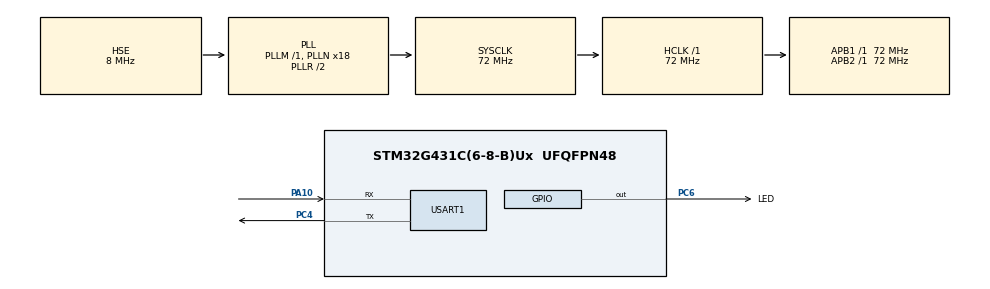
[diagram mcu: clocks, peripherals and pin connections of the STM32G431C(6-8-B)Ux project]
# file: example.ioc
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Mcu.Family=STM32G4
Mcu.Name=STM32G431C(6-8-B)Ux
Mcu.Package=UFQFPN48
NVIC.PriorityGroup=NVIC_PRIORITYGROUP_4
NVIC.TIM7_IRQn=true\:0\:0\:false\:false\:true\:true\:true\:true
PA10.Mode=Asynchronous
PA10.Signal=USART1_RX
PA13.Mode=Serial_Wire
PA13.Signal=SYS_JTMS-SWDIO
PA14.Mode=Serial_Wire
PA14.Signal=SYS_JTCK-SWCLK
PC4.Mode=Asynchronous
PC4.Signal=USART1_TX
PC6.GPIO_Label=LED
PC6.Signal=GPIO_Output
PF0-OSC_IN.Mode=HSE-External-Oscillator
PF0-OSC_IN.Signal=RCC_OSC_IN
PF1-OSC_OUT.Mode=HSE-External-Oscillator
PF1-OSC_OUT.Signal=RCC_OSC_OUT
ProjectManager.HeapSize=0x200
ProjectManager.StackSize=0x400
ProjectManager.TargetToolchain=CMake
RCC.ADC12Freq_Value=72000000
RCC.AHBFreq_Value=72000000
RCC.APB1Freq_Value=72000000
RCC.APB1TimFreq_Value=72000000
RCC.APB2Freq_Value=72000000
RCC.APB2TimFreq_Value=72000000
RCC.CortexFreq_Value=72000000
RCC.EXTERNAL_CLOCK_VALUE=12288000
RCC.HCLKFreq_Value=72000000
RCC.HSE_VALUE=8000000
RCC.HSI48_VALUE=48000000
RCC.HSI_VALUE=16000000
RCC.LSE_VALUE=32768
RCC.PLLN=18
RCC.PLLSourceVirtual=RCC_PLLSOURCE_HSE
RCC.SYSCLKFreq_VALUE=72000000
RCC.SYSCLKSource=RCC_SYSCLKSOURCE_PLLCLK
RCC.USBFreq_Value=72000000
RCC.VCOOutputFreq_Value=144000000
TIM7.PeriodNoDither=100-1
TIM7.Prescaler=72-1
USART1.VirtualMode-Asynchronous=VM_ASYNC
VP_SYS_VS_DBSignals.Mode=DisableDeadBatterySignals
VP_TIM7_VS_ClockSourceINT.Mode=Enable_Timer
board=custom

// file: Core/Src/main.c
/* USER CODE BEGIN Header */
/**
  ******************************************************************************
  * @file           : main.c
  * @brief          : Main program body
  ******************************************************************************
  * @attention
  *
  * Copyright (c) 2024 STMicroelectronics.
  * All rights reserved.
  *
  * This software is licensed under terms that can be found in the LICENSE file
  * in the root directory of this software component.
  * If no LICENSE file comes with this software, it is provided AS-IS.
  *
  ******************************************************************************
  */
/* USER CODE END Header */
#include "main.h"

/* USER CODE BEGIN Includes */
#include <string.h>
#include <stdio.h>
#include "dataAcq.h"
/* USER CODE END Includes */

TIM_HandleTypeDef htim7;

UART_HandleTypeDef huart1;

/* USER CODE BEGIN PV */
uint16_t counter=0;
uint8_t led_state=0;
uint16_t retardo=10;
char message[]="Hello World, Uart\r\n";

/* USER CODE END PV */

void SystemClock_Config(void);
static void MX_GPIO_Init(void);
static void MX_USART1_UART_Init(void);
static void MX_TIM7_Init(void);

/* USER CODE BEGIN 0 */
int __io_putchar(int ch){
    HAL_UART_Transmit(&huart1,(uint8_t *)&ch,1,100);
    return ch;
}
void HAL_TIM_PeriodElapsedCallback(TIM_HandleTypeDef *htim)
{
	if(htim == &htim7)
	{
        DumpTrace();
  }
}
/* USER CODE END 0 */

int main(void)
{

  /* MCU Configuration--------------------------------------------------------*/

  /* Reset of all peripherals, Initializes the Flash interface and the Systick. */
  HAL_Init();

  /* Configure the system clock */
  SystemClock_Config();

  /* Initialize all configured peripherals */
  MX_GPIO_Init();
  MX_USART1_UART_Init();
  MX_TIM7_Init();
  /* USER CODE BEGIN 2 */
   ClearBuffer();
   HAL_TIM_Base_Start_IT(&htim7);

  /* USER CODE END 2 */

  /* Infinite loop */
  /* USER CODE BEGIN WHILE */
  while (1)
  {
    led_state=!led_state;
    if(led_state)
      HAL_GPIO_WritePin(LED_GPIO_Port,LED_Pin,GPIO_PIN_SET);
    else
      HAL_GPIO_WritePin(LED_GPIO_Port,LED_Pin,GPIO_PIN_RESET);
   // HAL_UART_Transmit(&huart1,(uint8_t *)message,strlen(message),100);
   counter++;
   if(counter>=50) counter=0;
   ///printf("%.2f\r\n",counter);
    HAL_Delay(retardo);
    /* USER CODE END WHILE */

  }
}

void SystemClock_Config(void)
{
  RCC_OscInitTypeDef RCC_OscInitStruct = {0};
  RCC_ClkInitTypeDef RCC_ClkInitStruct = {0};

  /** Configure the main internal regulator output voltage
  */
  HAL_PWREx_ControlVoltageScaling(PWR_REGULATOR_VOLTAGE_SCALE1);

  /** Initializes the RCC Oscillators according to the specified parameters
  * in the RCC_OscInitTypeDef structure.
  */
  RCC_OscInitStruct.OscillatorType = RCC_OSCILLATORTYPE_HSE;
  RCC_OscInitStruct.HSEState = RCC_HSE_ON;
  RCC_OscInitStruct.PLL.PLLState = RCC_PLL_ON;
  RCC_OscInitStruct.PLL.PLLSource = RCC_PLLSOURCE_HSE;
  RCC_OscInitStruct.PLL.PLLM = RCC_PLLM_DIV1;
  RCC_OscInitStruct.PLL.PLLN = 18;
  RCC_OscInitStruct.PLL.PLLP = RCC_PLLP_DIV2;
  RCC_OscInitStruct.PLL.PLLQ = RCC_PLLQ_DIV2;
  RCC_OscInitStruct.PLL.PLLR = RCC_PLLR_DIV2;
  if (HAL_RCC_OscConfig(&RCC_OscInitStruct) != HAL_OK)
  {
    Error_Handler();
  }

  /** Initializes the CPU, AHB and APB buses clocks
  */
  RCC_ClkInitStruct.ClockType = RCC_CLOCKTYPE_HCLK|RCC_CLOCKTYPE_SYSCLK
                              |RCC_CLOCKTYPE_PCLK1|RCC_CLOCKTYPE_PCLK2;
  RCC_ClkInitStruct.SYSCLKSource = RCC_SYSCLKSOURCE_PLLCLK;
  RCC_ClkInitStruct.AHBCLKDivider = RCC_SYSCLK_DIV1;
  RCC_ClkInitStruct.APB1CLKDivider = RCC_HCLK_DIV1;
  RCC_ClkInitStruct.APB2CLKDivider = RCC_HCLK_DIV1;

  if (HAL_RCC_ClockConfig(&RCC_ClkInitStruct, FLASH_LATENCY_2) != HAL_OK)
  {
    Error_Handler();
  }
}

static void MX_TIM7_Init(void)
{

  TIM_MasterConfigTypeDef sMasterConfig = {0};

  htim7.Instance = TIM7;
  htim7.Init.Prescaler = 72-1;
  htim7.Init.CounterMode = TIM_COUNTERMODE_UP;
  htim7.Init.Period = 99;
  htim7.Init.AutoReloadPreload = TIM_AUTORELOAD_PRELOAD_DISABLE;
  if (HAL_TIM_Base_Init(&htim7) != HAL_OK)
  {
    Error_Handler();
  }
  sMasterConfig.MasterOutputTrigger = TIM_TRGO_RESET;
  sMasterConfig.MasterSlaveMode = TIM_MASTERSLAVEMODE_DISABLE;
  if (HAL_TIMEx_MasterConfigSynchronization(&htim7, &sMasterConfig) != HAL_OK)
  {
    Error_Handler();
  }

}

static void MX_USART1_UART_Init(void)
{

  huart1.Instance = USART1;
  huart1.Init.BaudRate = 115200;
  huart1.Init.WordLength = UART_WORDLENGTH_8B;
  huart1.Init.StopBits = UART_STOPBITS_1;
  huart1.Init.Parity = UART_PARITY_NONE;
  huart1.Init.Mode = UART_MODE_TX_RX;
  huart1.Init.HwFlowCtl = UART_HWCONTROL_NONE;
  huart1.Init.OverSampling = UART_OVERSAMPLING_16;
  huart1.Init.OneBitSampling = UART_ONE_BIT_SAMPLE_DISABLE;
  huart1.Init.ClockPrescaler = UART_PRESCALER_DIV1;
  huart1.AdvancedInit.AdvFeatureInit = UART_ADVFEATURE_NO_INIT;
  if (HAL_UART_Init(&huart1) != HAL_OK)
  {
    Error_Handler();
  }
  if (HAL_UARTEx_SetTxFifoThreshold(&huart1, UART_TXFIFO_THRESHOLD_1_8) != HAL_OK)
  {
    Error_Handler();
  }
  if (HAL_UARTEx_SetRxFifoThreshold(&huart1, UART_RXFIFO_THRESHOLD_1_8) != HAL_OK)
  {
    Error_Handler();
  }
  if (HAL_UARTEx_DisableFifoMode(&huart1) != HAL_OK)
  {
    Error_Handler();
  }

}

static void MX_GPIO_Init(void)
{
  GPIO_InitTypeDef GPIO_InitStruct = {0};

  /* GPIO Ports Clock Enable */
  __HAL_RCC_GPIOF_CLK_ENABLE();
  __HAL_RCC_GPIOC_CLK_ENABLE();
  __HAL_RCC_GPIOA_CLK_ENABLE();

  /*Configure GPIO pin Output Level */
  HAL_GPIO_WritePin(LED_GPIO_Port, LED_Pin, GPIO_PIN_RESET);

  /*Configure GPIO pin : LED_Pin */
  GPIO_InitStruct.Pin = LED_Pin;
  GPIO_InitStruct.Mode = GPIO_MODE_OUTPUT_PP;
  GPIO_InitStruct.Pull = GPIO_NOPULL;
  GPIO_InitStruct.Speed = GPIO_SPEED_FREQ_LOW;
  HAL_GPIO_Init(LED_GPIO_Port, &GPIO_InitStruct);

}

void Error_Handler(void)
{
  __disable_irq();
  while (1)
  {
  }
}
